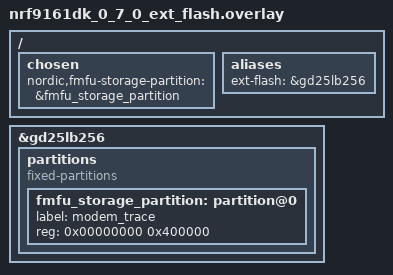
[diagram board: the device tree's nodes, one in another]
/*
 * Copyright (c) 2023 Nordic Semiconductor ASA
 *
 * SPDX-License-Identifier: LicenseRef-Nordic-5-Clause
 */

/delete-node/ &gd25wb256;

/ {
	chosen {
		nordic,fmfu-storage-partition = &fmfu_storage_partition;
	};

	aliases {
		ext-flash = &gd25lb256;
	};
};

&gd25lb256 {
	status = "okay";

	partitions {
		compatible = "fixed-partitions";
		#address-cells = <1>;
		#size-cells = <1>;

		fmfu_storage_partition: partition@0 {
			label = "modem_trace";
			reg = <0x00000000 0x400000>;
		};
	};
};
